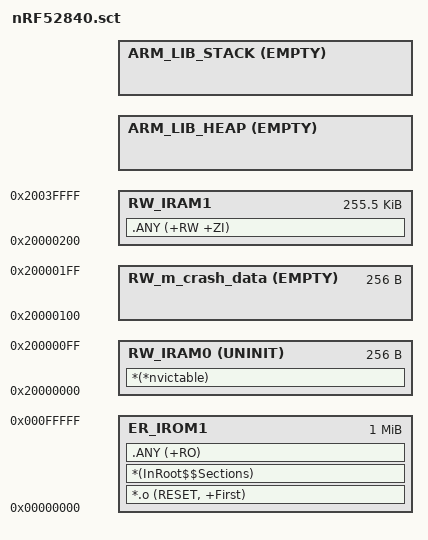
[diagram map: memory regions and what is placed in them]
#! armcc -E

/* Default to no softdevice */
#if !defined(MBED_APP_START)
  #define MBED_APP_START 0x0
#endif

#if !defined(MBED_APP_SIZE)
  #define MBED_APP_SIZE 0x100000
#endif

#if !defined(MBED_RAM_START)
  #define MBED_RAM_START 0x20000000
  #define MBED_RAM_SIZE 0x40000
#endif

#define Stack_Size MBED_BOOT_STACK_SIZE

#define MBED_RAM0_START MBED_RAM_START
#define MBED_RAM0_SIZE  0x100

#define MBED_CRASH_REPORT_RAM_START (MBED_RAM0_START + MBED_RAM0_SIZE)
#define MBED_CRASH_REPORT_RAM_SIZE  0x100

#define MBED_RAM1_START (MBED_CRASH_REPORT_RAM_START + MBED_CRASH_REPORT_RAM_SIZE)
#define MBED_RAM1_SIZE  (MBED_RAM_SIZE - (MBED_RAM0_SIZE + MBED_CRASH_REPORT_RAM_SIZE))


#define RAM_FIXED_SIZE   (MBED_BOOT_STACK_SIZE+MBED_RAM0_SIZE+MBED_CRASH_REPORT_RAM_SIZE)

LR_IROM1 MBED_APP_START MBED_APP_SIZE {
  ER_IROM1 MBED_APP_START MBED_APP_SIZE {
   *.o (RESET, +First)
   *(InRoot$$Sections)
   .ANY (+RO)
  }
  RW_IRAM0 MBED_RAM0_START UNINIT MBED_RAM0_SIZE { ;no init section
        *(*nvictable)
  }
  RW_m_crash_data MBED_CRASH_REPORT_RAM_START EMPTY MBED_CRASH_REPORT_RAM_SIZE { ; RW data
  }
  RW_IRAM1 MBED_RAM1_START MBED_RAM1_SIZE {
   .ANY (+RW +ZI)
  }
  ARM_LIB_HEAP  AlignExpr(+0, 16)  EMPTY  (MBED_RAM_SIZE-RAM_FIXED_SIZE+MBED_RAM_START-AlignExpr(ImageLimit(RW_IRAM1), 16))  {
  }
  ARM_LIB_STACK MBED_RAM1_START+MBED_RAM1_SIZE EMPTY -Stack_Size { ; Stack region growing down
  }
}
